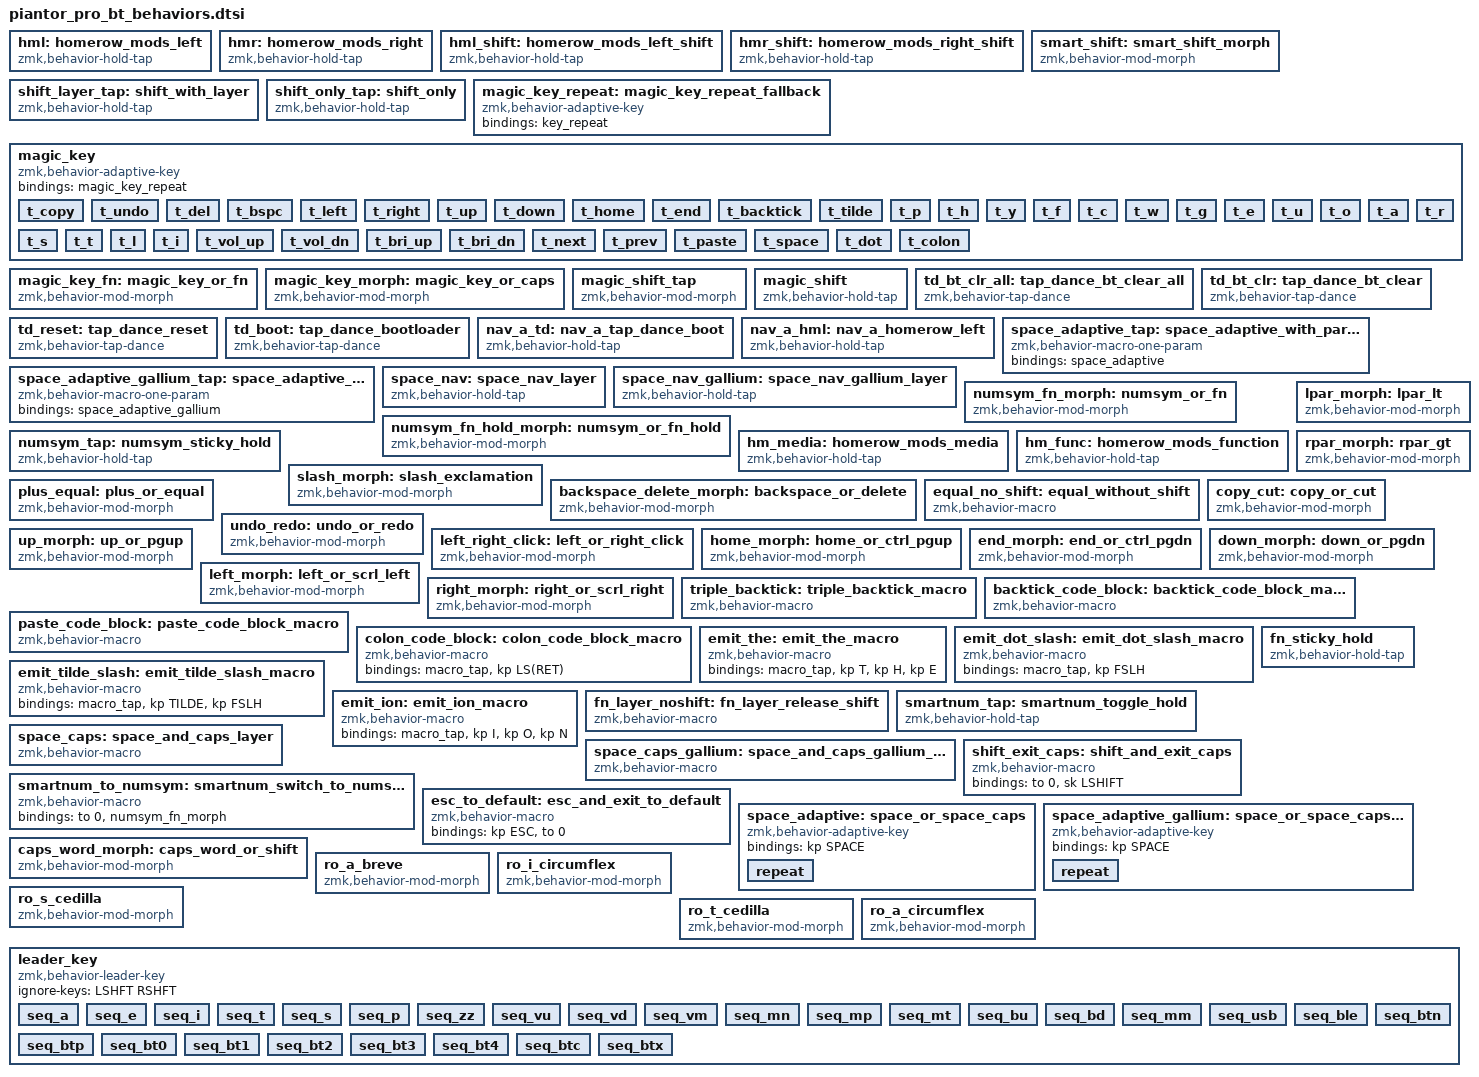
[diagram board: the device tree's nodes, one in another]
// Custom behaviors for Piantor Pro BT
hml: homerow_mods_left {
    compatible = "zmk,behavior-hold-tap";
    #binding-cells = <2>;
    flavor = "balanced";
    require-prior-idle-ms = <150>;
    tapping-term-ms = <280>;
    quick-tap-ms = <175>;
    bindings = <&kp>, <&kp>;
    hold-trigger-key-positions = <5 6 7 8 9 15 16 17 18 19 25 26 27 28 29 33 34 35>;
    hold-trigger-on-release;
};
hmr: homerow_mods_right {
    compatible = "zmk,behavior-hold-tap";
    #binding-cells = <2>;
    flavor = "balanced";
    require-prior-idle-ms = <150>;
    tapping-term-ms = <280>;
    quick-tap-ms = <175>;
    bindings = <&kp>, <&kp>;
    hold-trigger-key-positions = <0 1 2 3 4 10 11 12 13 14 20 21 22 23 24 30 31 32>;
    hold-trigger-on-release;
};
hml_shift: homerow_mods_left_shift {
    compatible = "zmk,behavior-hold-tap";
    #binding-cells = <2>;
    flavor = "balanced";
    require-prior-idle-ms = <120>;
    tapping-term-ms = <200>;
    quick-tap-ms = <175>;
    bindings = <&kp>, <&kp>;
    hold-trigger-key-positions = <5 6 7 8 9 15 16 17 18 19 25 26 27 28 29 33 34 35>;
    hold-trigger-on-release;
};
hmr_shift: homerow_mods_right_shift {
    compatible = "zmk,behavior-hold-tap";
    #binding-cells = <2>;
    flavor = "balanced";
    require-prior-idle-ms = <120>;
    tapping-term-ms = <200>;
    quick-tap-ms = <175>;
    bindings = <&kp>, <&kp>;
    hold-trigger-key-positions = <0 1 2 3 4 10 11 12 13 14 20 21 22 23 24 30 31 32>;
    hold-trigger-on-release;
};
smart_shift: smart_shift_morph {
    compatible = "zmk,behavior-mod-morph";
    #binding-cells = <0>;
    bindings = <&sk LSHIFT>, <&caps_word>;
    mods = <(MOD_LSFT|MOD_RSFT)>;
};
shift_layer_tap: shift_with_layer {
    compatible = "zmk,behavior-hold-tap";
    #binding-cells = <2>;
    flavor = "balanced";
    tapping-term-ms = <280>;
    quick-tap-ms = <225>;
    bindings = <&mo>, <&smart_shift>;
};
shift_only_tap: shift_only {
    compatible = "zmk,behavior-hold-tap";
    #binding-cells = <2>;
    flavor = "balanced";
    tapping-term-ms = <280>;
    quick-tap-ms = <225>;
    bindings = <&kp>, <&smart_shift>;
};

// urob's magic key: tap after special keys = special action, otherwise = repeat
// Flat structure with all triggers as child nodes (no chaining to prevent stack overflow)
magic_key_repeat: magic_key_repeat_fallback {
    compatible = "zmk,behavior-adaptive-key";
    #binding-cells = <0>;
    bindings = <&key_repeat>;
};
magic_key: magic_key {
    compatible = "zmk,behavior-adaptive-key";
    #binding-cells = <0>;
    bindings = <&magic_key_repeat>;

    t_copy {
        trigger-keys = <K_COPY>;
        bindings = <&kp K_CUT>;
        max-prior-idle-ms = <5000>;
        strict-modifiers;
    };
    t_undo {
        trigger-keys = <K_UNDO>;
        bindings = <&kp K_AGAIN>;
        max-prior-idle-ms = <5000>;
        strict-modifiers;
    };
    t_del {
        trigger-keys = <DEL>;
        bindings = <&kp LC(DEL)>;
        max-prior-idle-ms = <5000>;
    };
    t_bspc {
        trigger-keys = <BSPC>;
        bindings = <&kp LC(BSPC)>;
        max-prior-idle-ms = <5000>;
    };
    t_left {
        trigger-keys = <LEFT>;
        bindings = <&kp LC(LEFT)>;
        max-prior-idle-ms = <5000>;
        strict-modifiers;
    };
    t_right {
        trigger-keys = <RIGHT>;
        bindings = <&kp LC(RIGHT)>;
        max-prior-idle-ms = <5000>;
        strict-modifiers;
    };
    t_up {
        trigger-keys = <UP>;
        bindings = <&kp LC(PG_UP)>;
        max-prior-idle-ms = <5000>;
        strict-modifiers;
    };
    t_down {
        trigger-keys = <DOWN>;
        bindings = <&kp LC(PG_DN)>;
        max-prior-idle-ms = <5000>;
        strict-modifiers;
    };
    t_home {
        trigger-keys = <HOME>;
        bindings = <&kp LC(HOME)>;
        max-prior-idle-ms = <5000>;
        strict-modifiers;
    };
    t_end {
        trigger-keys = <END>;
        bindings = <&kp LC(END)>;
        max-prior-idle-ms = <5000>;
        strict-modifiers;
    };
    t_backtick {
        trigger-keys = <GRAVE>;
        bindings = <&backtick_code_block>;
        max-prior-idle-ms = <5000>;
        strict-modifiers;
    };
    t_tilde {
        trigger-keys = <TILDE>;
        bindings = <&kp FSLH>;
        max-prior-idle-ms = <5000>;
        strict-modifiers;
    };
    t_p {
        trigger-keys = <P>;
        bindings = <&kp H>;
        max-prior-idle-ms = <5000>;
    };
    t_h {
        trigger-keys = <H>;
        bindings = <&kp Y>;
        max-prior-idle-ms = <5000>;
    };
    t_y {
        trigger-keys = <Y>;
        bindings = <&kp P>;
        max-prior-idle-ms = <5000>;
    };
    t_f {
        trigger-keys = <F>;
        bindings = <&kp Y>;
        max-prior-idle-ms = <5000>;
    };
    t_c {
        trigger-keys = <C>;
        bindings = <&kp S>;
        max-prior-idle-ms = <5000>;
    };
    t_w {
        trigger-keys = <W>;
        bindings = <&kp S>;
        max-prior-idle-ms = <5000>;
    };
    t_g {
        trigger-keys = <G>;
        bindings = <&kp S>;
        max-prior-idle-ms = <5000>;
    };
    t_e {
        trigger-keys = <E>;
        bindings = <&kp U>;
        max-prior-idle-ms = <5000>;
    };
    t_u {
        trigger-keys = <U>;
        bindings = <&kp E>;
        max-prior-idle-ms = <5000>;
    };
    t_o {
        trigger-keys = <O>;
        bindings = <&kp A>;
        max-prior-idle-ms = <5000>;
    };
    t_a {
        trigger-keys = <A>;
        bindings = <&kp O>;
        max-prior-idle-ms = <5000>;
    };
    t_r {
        trigger-keys = <R>;
        bindings = <&kp L>;
        max-prior-idle-ms = <5000>;
    };
    t_s {
        trigger-keys = <S>;
        bindings = <&kp C>;
        max-prior-idle-ms = <5000>;
    };
    t_t {
        trigger-keys = <T>;
        bindings = <&emit_ion>;
        max-prior-idle-ms = <5000>;
    };
    t_l {
        trigger-keys = <L>;
        bindings = <&kp R>;
        max-prior-idle-ms = <5000>;
    };
    t_i {
        trigger-keys = <I>;
        bindings = <&kp SQT>;
        max-prior-idle-ms = <5000>;
    };
    t_vol_up {
        trigger-keys = <C_VOL_UP>;
        bindings = <&kp C_VOL_UP>;
        max-prior-idle-ms = <5000>;
    };
    t_vol_dn {
        trigger-keys = <C_VOL_DN>;
        bindings = <&kp C_VOL_DN>;
        max-prior-idle-ms = <5000>;
    };
    t_bri_up {
        trigger-keys = <C_BRI_UP>;
        bindings = <&kp C_BRI_UP>;
        max-prior-idle-ms = <5000>;
    };
    t_bri_dn {
        trigger-keys = <C_BRI_DN>;
        bindings = <&kp C_BRI_DN>;
        max-prior-idle-ms = <5000>;
    };
    t_next {
        trigger-keys = <C_NEXT>;
        bindings = <&kp C_NEXT>;
        max-prior-idle-ms = <5000>;
    };
    t_prev {
        trigger-keys = <C_PREV>;
        bindings = <&kp C_PREV>;
        max-prior-idle-ms = <5000>;
    };
    t_paste {
        trigger-keys = <K_PASTE>;
        bindings = <&paste_code_block>;
        max-prior-idle-ms = <5000>;
        strict-modifiers;
    };
    t_space {
        trigger-keys = <SPACE>;
        bindings = <&kp LS(I)>;
        max-prior-idle-ms = <5000>;
        strict-modifiers;
    };
    t_dot {
        trigger-keys = <DOT>;
        bindings = <&emit_dot_slash>;
        max-prior-idle-ms = <5000>;
        strict-modifiers;
    };
    t_colon {
        trigger-keys = <COLON>;
        bindings = <&colon_code_block>;
        max-prior-idle-ms = <5000>;
        strict-modifiers;
    };
};
magic_key_fn: magic_key_or_fn {
    compatible = "zmk,behavior-mod-morph";
    #binding-cells = <0>;
    bindings = <&magic_key>, <&sl 2>;
    mods = <(MOD_LALT|MOD_RALT)>;
};
magic_key_morph: magic_key_or_caps {
    compatible = "zmk,behavior-mod-morph";
    #binding-cells = <0>;
    bindings = <&magic_key_fn>, <&caps_word>;
    mods = <(MOD_LSFT|MOD_RSFT)>;
};
magic_shift_tap: magic_shift_tap {
    compatible = "zmk,behavior-mod-morph";
    #binding-cells = <0>;
    bindings = <&sk LSHIFT>, <&caps_word>;
    mods = <(MOD_LSFT)>;
};
magic_shift: magic_shift {
    compatible = "zmk,behavior-hold-tap";
    #binding-cells = <2>;
    flavor = "tap-preferred";
    tapping-term-ms = <200>;
    quick-tap-ms = <175>;
    bindings = <&kp>, <&magic_shift_tap>;
};

// Tap-dance behaviors for dangerous actions (require double-tap)
td_bt_clr_all: tap_dance_bt_clear_all {
    compatible = "zmk,behavior-tap-dance";
    #binding-cells = <0>;
    tapping-term-ms = <1000>;
    bindings = <&none>, <&bt BT_CLR_ALL>;
};
td_bt_clr: tap_dance_bt_clear {
    compatible = "zmk,behavior-tap-dance";
    #binding-cells = <0>;
    tapping-term-ms = <1000>;
    bindings = <&none>, <&bt BT_CLR>;
};
td_reset: tap_dance_reset {
    compatible = "zmk,behavior-tap-dance";
    #binding-cells = <0>;
    tapping-term-ms = <1000>;
    bindings = <&none>, <&sys_reset>;
};
td_boot: tap_dance_bootloader {
    compatible = "zmk,behavior-tap-dance";
    #binding-cells = <0>;
    tapping-term-ms = <1000>;
    bindings = <&none>, <&bootloader>;
};

// Nav layer position A: tap=boot (double-tap only), hold=alt (matches hml timing)
nav_a_td: nav_a_tap_dance_boot {
    compatible = "zmk,behavior-hold-tap";
    #binding-cells = <2>;
    flavor = "balanced";
    require-prior-idle-ms = <150>;
    tapping-term-ms = <280>;
    quick-tap-ms = <175>;
    bindings = <&kp>, <&td_boot>;
    hold-trigger-key-positions = <5 6 7 8 9 15 16 17 18 19 25 26 27 28 29 33 34 35>;
    hold-trigger-on-release;
};
// Nav layer position A: tap=reset, hold=alt (matches hml timing)
nav_a_hml: nav_a_homerow_left {
    compatible = "zmk,behavior-hold-tap";
    #binding-cells = <2>;
    flavor = "balanced";
    require-prior-idle-ms = <150>;
    tapping-term-ms = <280>;
    quick-tap-ms = <175>;
    bindings = <&kp>, <&sys_reset>;
    hold-trigger-key-positions = <5 6 7 8 9 15 16 17 18 19 25 26 27 28 29 33 34 35>;
    hold-trigger-on-release;
};
space_adaptive_tap: space_adaptive_with_param {
    compatible = "zmk,behavior-macro-one-param";
    #binding-cells = <1>;
    bindings = <&space_adaptive>;
};
space_adaptive_gallium_tap: space_adaptive_gallium_with_param {
    compatible = "zmk,behavior-macro-one-param";
    #binding-cells = <1>;
    bindings = <&space_adaptive_gallium>;
};
// Space nav layer: tap=space_adaptive (auto-caps after punctuation), hold=nav_sys layer (only triggers on left-side keys)
space_nav: space_nav_layer {
    compatible = "zmk,behavior-hold-tap";
    #binding-cells = <2>;
    flavor = "balanced";
    require-prior-idle-ms = <150>;
    tapping-term-ms = <280>;
    quick-tap-ms = <175>;
    bindings = <&mo>, <&space_adaptive_tap>;
    hold-trigger-key-positions = <0 1 2 3 4 10 11 12 13 14 20 21 22 23 24 30 31 32>;
    hold-trigger-on-release;
};
space_nav_gallium: space_nav_gallium_layer {
    compatible = "zmk,behavior-hold-tap";
    #binding-cells = <2>;
    flavor = "balanced";
    require-prior-idle-ms = <150>;
    tapping-term-ms = <280>;
    quick-tap-ms = <175>;
    bindings = <&mo>, <&space_adaptive_gallium_tap>;
    hold-trigger-key-positions = <0 1 2 3 4 10 11 12 13 14 20 21 22 23 24 30 31 32>;
    hold-trigger-on-release;
};
numsym_fn_morph: numsym_or_fn {
    compatible = "zmk,behavior-mod-morph";
    #binding-cells = <0>;
    bindings = <&sl 3>, <&fn_layer_noshift>;
    mods = <(MOD_LSFT|MOD_RSFT)>;
};
numsym_fn_hold_morph: numsym_or_fn_hold {
    compatible = "zmk,behavior-mod-morph";
    #binding-cells = <0>;
    bindings = <&mo 3>, <&mo 2>;
    mods = <(MOD_LSFT|MOD_RSFT)>;
};
numsym_tap: numsym_sticky_hold {
    compatible = "zmk,behavior-hold-tap";
    #binding-cells = <2>;
    flavor = "balanced";
    tapping-term-ms = <280>;
    quick-tap-ms = <225>;
    bindings = <&numsym_fn_hold_morph>, <&numsym_fn_morph>;
};
// System layer media key home row mods
hm_media: homerow_mods_media {
    compatible = "zmk,behavior-hold-tap";
    #binding-cells = <2>;
    flavor = "balanced";
    tapping-term-ms = <280>;
    quick-tap-ms = <225>;
    bindings = <&kp>, <&kp>;
};
// System layer function key home row mods
hm_func: homerow_mods_function {
    compatible = "zmk,behavior-hold-tap";
    #binding-cells = <2>;
    flavor = "balanced";
    tapping-term-ms = <280>;
    quick-tap-ms = <225>;
    bindings = <&kp>, <&kp>;
};

// Custom shift behaviors for slash
slash_morph: slash_exclamation {
    compatible = "zmk,behavior-mod-morph";
    #binding-cells = <0>;
    bindings = <&kp QMARK>, <&kp EXCL>;
    mods = <(MOD_LSFT|MOD_RSFT)>;
};
backspace_delete_morph: backspace_or_delete {
    compatible = "zmk,behavior-mod-morph";
    #binding-cells = <0>;
    bindings = <&kp BSPC>, <&kp DEL>;
    mods = <(MOD_LSFT|MOD_RSFT)>;
};
lpar_morph: lpar_lt {
    compatible = "zmk,behavior-mod-morph";
    #binding-cells = <0>;
    bindings = <&kp LPAR>, <&kp LT>;
    mods = <(MOD_LSFT|MOD_RSFT)>;
};
rpar_morph: rpar_gt {
    compatible = "zmk,behavior-mod-morph";
    #binding-cells = <0>;
    bindings = <&kp RPAR>, <&kp GT>;
    mods = <(MOD_LSFT|MOD_RSFT)>;
};
equal_no_shift: equal_without_shift {
    compatible = "zmk,behavior-macro";
    #binding-cells = <0>;
    bindings = <&macro_release &kp LSHIFT &kp RSHIFT>, <&macro_tap &kp EQUAL>;
};
plus_equal: plus_or_equal {
    compatible = "zmk,behavior-mod-morph";
    #binding-cells = <0>;
    bindings = <&kp PLUS>, <&equal_no_shift>;
    mods = <(MOD_LSFT|MOD_RSFT)>;
};
copy_cut: copy_or_cut {
    compatible = "zmk,behavior-mod-morph";
    #binding-cells = <0>;
    bindings = <&kp K_COPY>, <&kp K_CUT>;
    mods = <(MOD_LSFT|MOD_RSFT)>;
};
undo_redo: undo_or_redo {
    compatible = "zmk,behavior-mod-morph";
    #binding-cells = <0>;
    bindings = <&kp K_UNDO>, <&kp K_AGAIN>;
    mods = <(MOD_LSFT|MOD_RSFT)>;
};
left_right_click: left_or_right_click {
    compatible = "zmk,behavior-mod-morph";
    #binding-cells = <0>;
    bindings = <&mkp MB1>, <&mkp MB2>;
    mods = <(MOD_LSFT|MOD_RSFT)>;
};
home_morph: home_or_ctrl_pgup {
    compatible = "zmk,behavior-mod-morph";
    #binding-cells = <0>;
    bindings = <&kp HOME>, <&kp LC(PG_UP)>;
    mods = <(MOD_LGUI|MOD_RGUI)>;
};
end_morph: end_or_ctrl_pgdn {
    compatible = "zmk,behavior-mod-morph";
    #binding-cells = <0>;
    bindings = <&kp END>, <&kp LC(PG_DN)>;
    mods = <(MOD_LGUI|MOD_RGUI)>;
};
up_morph: up_or_pgup {
    compatible = "zmk,behavior-mod-morph";
    #binding-cells = <0>;
    bindings = <&kp UP>, <&kp PG_UP>;
    mods = <(MOD_LGUI|MOD_RGUI)>;
};
down_morph: down_or_pgdn {
    compatible = "zmk,behavior-mod-morph";
    #binding-cells = <0>;
    bindings = <&kp DOWN>, <&kp PG_DN>;
    mods = <(MOD_LGUI|MOD_RGUI)>;
};
left_morph: left_or_scrl_left {
    compatible = "zmk,behavior-mod-morph";
    #binding-cells = <0>;
    bindings = <&kp LEFT>, <&msc SCRL_LEFT>;
    mods = <(MOD_LGUI|MOD_RGUI)>;
};
right_morph: right_or_scrl_right {
    compatible = "zmk,behavior-mod-morph";
    #binding-cells = <0>;
    bindings = <&kp RIGHT>, <&msc SCRL_RIGHT>;
    mods = <(MOD_LGUI|MOD_RGUI)>;
};
triple_backtick: triple_backtick_macro {
    compatible = "zmk,behavior-macro";
    #binding-cells = <0>;
    bindings = <&macro_tap &kp GRAVE &kp GRAVE &kp GRAVE>;
};
backtick_code_block: backtick_code_block_macro {
    compatible = "zmk,behavior-macro";
    #binding-cells = <0>;
    bindings = <&macro_tap &kp GRAVE &kp GRAVE &kp LS(RET)>;
};
paste_code_block: paste_code_block_macro {
    compatible = "zmk,behavior-macro";
    #binding-cells = <0>;
    bindings = <&macro_tap &kp LS(RET) &kp GRAVE &kp GRAVE &kp GRAVE &kp LS(RET)>;
};
colon_code_block: colon_code_block_macro {
    compatible = "zmk,behavior-macro";
    #binding-cells = <0>;
    bindings = <&macro_tap &kp LS(RET)>;
};
emit_the: emit_the_macro {
    compatible = "zmk,behavior-macro";
    #binding-cells = <0>;
    bindings = <&macro_tap &kp T &kp H &kp E>;
};
emit_dot_slash: emit_dot_slash_macro {
    compatible = "zmk,behavior-macro";
    #binding-cells = <0>;
    bindings = <&macro_tap &kp FSLH>;
};
emit_tilde_slash: emit_tilde_slash_macro {
    compatible = "zmk,behavior-macro";
    #binding-cells = <0>;
    bindings = <&macro_tap &kp TILDE &kp FSLH>;
};
emit_ion: emit_ion_macro {
    compatible = "zmk,behavior-macro";
    #binding-cells = <0>;
    bindings = <&macro_tap &kp I &kp O &kp N>;
};
fn_layer_noshift: fn_layer_release_shift {
    compatible = "zmk,behavior-macro";
    #binding-cells = <0>;
    bindings = <&sl 2>, <&macro_release &kp LSHIFT &kp RSHIFT>;
};
smartnum_tap: smartnum_toggle_hold {
    compatible = "zmk,behavior-hold-tap";
    #binding-cells = <2>;
    flavor = "balanced";
    tapping-term-ms = <280>;
    quick-tap-ms = <225>;
    bindings = <&mo>, <&num_word>;
};
fn_sticky_hold: fn_sticky_hold {
    compatible = "zmk,behavior-hold-tap";
    #binding-cells = <2>;
    flavor = "balanced";
    tapping-term-ms = <280>;
    quick-tap-ms = <225>;
    bindings = <&mo>, <&sl>;
};
space_caps: space_and_caps_layer {
    compatible = "zmk,behavior-macro";
    #binding-cells = <0>;
    tap-ms = <0>;
    wait-ms = <0>;
    bindings = <&kp SPACE>, <&sl 1>;
};
space_caps_gallium: space_and_caps_gallium_layer {
    compatible = "zmk,behavior-macro";
    #binding-cells = <0>;
    tap-ms = <0>;
    wait-ms = <0>;
    bindings = <&kp SPACE>, <&sl 1>;
};
shift_exit_caps: shift_and_exit_caps {
    compatible = "zmk,behavior-macro";
    #binding-cells = <0>;
    bindings = <&to 0>, <&sk LSHIFT>;
};
smartnum_to_numsym: smartnum_switch_to_numsym {
    compatible = "zmk,behavior-macro";
    #binding-cells = <0>;
    bindings = <&to 0>, <&numsym_fn_morph>;
};
esc_to_default: esc_and_exit_to_default {
    compatible = "zmk,behavior-macro";
    #binding-cells = <0>;
    bindings = <&kp ESC>, <&to 0>;
};
space_adaptive: space_or_space_caps {
    compatible = "zmk,behavior-adaptive-key";
    #binding-cells = <0>;
    bindings = <&kp SPACE>;
    repeat {
        trigger-keys = <DOT QMARK EXCL>;
        bindings = <&space_caps>;
        max-prior-idle-ms = <1000>;
        strict-modifiers;
    };
};
space_adaptive_gallium: space_or_space_caps_gallium {
    compatible = "zmk,behavior-adaptive-key";
    #binding-cells = <0>;
    bindings = <&kp SPACE>;
    repeat {
        trigger-keys = <DOT QMARK EXCL>;
        bindings = <&space_caps_gallium>;
        max-prior-idle-ms = <1000>;
        strict-modifiers;
    };
};

caps_word_morph: caps_word_or_shift {
    compatible = "zmk,behavior-mod-morph";
    #binding-cells = <0>;
    bindings = <&sk LSHFT>, <&caps_word>;
    mods = <(MOD_LSFT|MOD_RSFT)>;
};

// Romanian mod-morph behaviors: lowercase/uppercase via shift
ro_a_breve: ro_a_breve {
    compatible = "zmk,behavior-mod-morph";
    #binding-cells = <0>;
    bindings = <&kp RG(A)>, <&kp LS(RG(A))>;
    mods = <(MOD_LSFT|MOD_RSFT)>;
};
ro_i_circumflex: ro_i_circumflex {
    compatible = "zmk,behavior-mod-morph";
    #binding-cells = <0>;
    bindings = <&kp RG(I)>, <&kp LS(RG(I))>;
    mods = <(MOD_LSFT|MOD_RSFT)>;
};
ro_s_cedilla: ro_s_cedilla {
    compatible = "zmk,behavior-mod-morph";
    #binding-cells = <0>;
    bindings = <&kp RG(S)>, <&kp LS(RG(S))>;
    mods = <(MOD_LSFT|MOD_RSFT)>;
};
ro_t_cedilla: ro_t_cedilla {
    compatible = "zmk,behavior-mod-morph";
    #binding-cells = <0>;
    bindings = <&kp RG(T)>, <&kp LS(RG(T))>;
    mods = <(MOD_LSFT|MOD_RSFT)>;
};
ro_a_circumflex: ro_a_circumflex {
    compatible = "zmk,behavior-mod-morph";
    #binding-cells = <0>;
    bindings = <&kp RG(E)>, <&kp LS(RG(E))>;
    mods = <(MOD_LSFT|MOD_RSFT)>;
};

// Leader key: Romanian letters and system controls
leader_key: leader_key {
    compatible = "zmk,behavior-leader-key";
    #binding-cells = <0>;
    ignore-keys = <LSHFT RSHFT>;
    // Romanian letters via Right Super: A=ă/Ă, E=â/Â, I=î/Î, T=ț/Ț, S=ș/Ș
    seq_a {
        sequence = <A>;
        bindings = <&ro_a_breve>;
    };
    seq_e {
        sequence = <E>;
        bindings = <&ro_a_circumflex>;
    };
    seq_i {
        sequence = <I>;
        bindings = <&ro_i_circumflex>;
    };
    seq_t {
        sequence = <T>;
        bindings = <&ro_t_cedilla>;
    };
    seq_s {
        sequence = <S>;
        bindings = <&ro_s_cedilla>;
    };
    // System controls
    seq_p {
        sequence = <P>;
        bindings = <&kp PSCRN>;
    };
    seq_zz {
        sequence = <Z Z>;
        bindings = <&kp C_SLEEP>;
    };
    // Volume controls
    seq_vu {
        sequence = <V U>;
        bindings = <&kp C_VOL_UP>;
    };
    seq_vd {
        sequence = <V D>;
        bindings = <&kp C_VOL_DN>;
    };
    seq_vm {
        sequence = <V M>;
        bindings = <&kp C_MUTE>;
    };
    // Media controls
    seq_mn {
        sequence = <M N>;
        bindings = <&kp C_NEXT>;
    };
    seq_mp {
        sequence = <M P>;
        bindings = <&kp C_PREV>;
    };
    seq_mt {
        sequence = <M T>;
        bindings = <&kp C_PP>;
    };
    // Brightness controls
    seq_bu {
        sequence = <B U>;
        bindings = <&kp C_BRI_UP>;
    };
    seq_bd {
        sequence = <B D>;
        bindings = <&kp C_BRI_DN>;
    };
    // Mic mute
    seq_mm {
        sequence = <M M>;
        bindings = <&kp F20>;
    };
    // Output mode
    seq_usb {
        sequence = <U S B>;
        bindings = <&out OUT_USB>;
    };
    seq_ble {
        sequence = <B L E>;
        bindings = <&out OUT_BLE>;
    };
    // Bluetooth controls
    seq_btn {
        sequence = <B T N>;
        bindings = <&bt BT_NXT>;
    };
    seq_btp {
        sequence = <B T P>;
        bindings = <&bt BT_PRV>;
    };
    seq_bt0 {
        sequence = <B T N0>;
        bindings = <&bt BT_SEL 0>;
    };
    seq_bt1 {
        sequence = <B T N1>;
        bindings = <&bt BT_SEL 1>;
    };
    seq_bt2 {
        sequence = <B T N2>;
        bindings = <&bt BT_SEL 2>;
    };
    seq_bt3 {
        sequence = <B T N3>;
        bindings = <&bt BT_SEL 3>;
    };
    seq_bt4 {
        sequence = <B T N4>;
        bindings = <&bt BT_SEL 4>;
    };
    seq_btc {
        sequence = <B T C>;
        bindings = <&bt BT_CLR>;
    };
    seq_btx {
        sequence = <B T X>;
        bindings = <&bt BT_CLR_ALL>;
    };
    // RGB controls removed: RGB underglow is compiled out (see defconfig).
};


